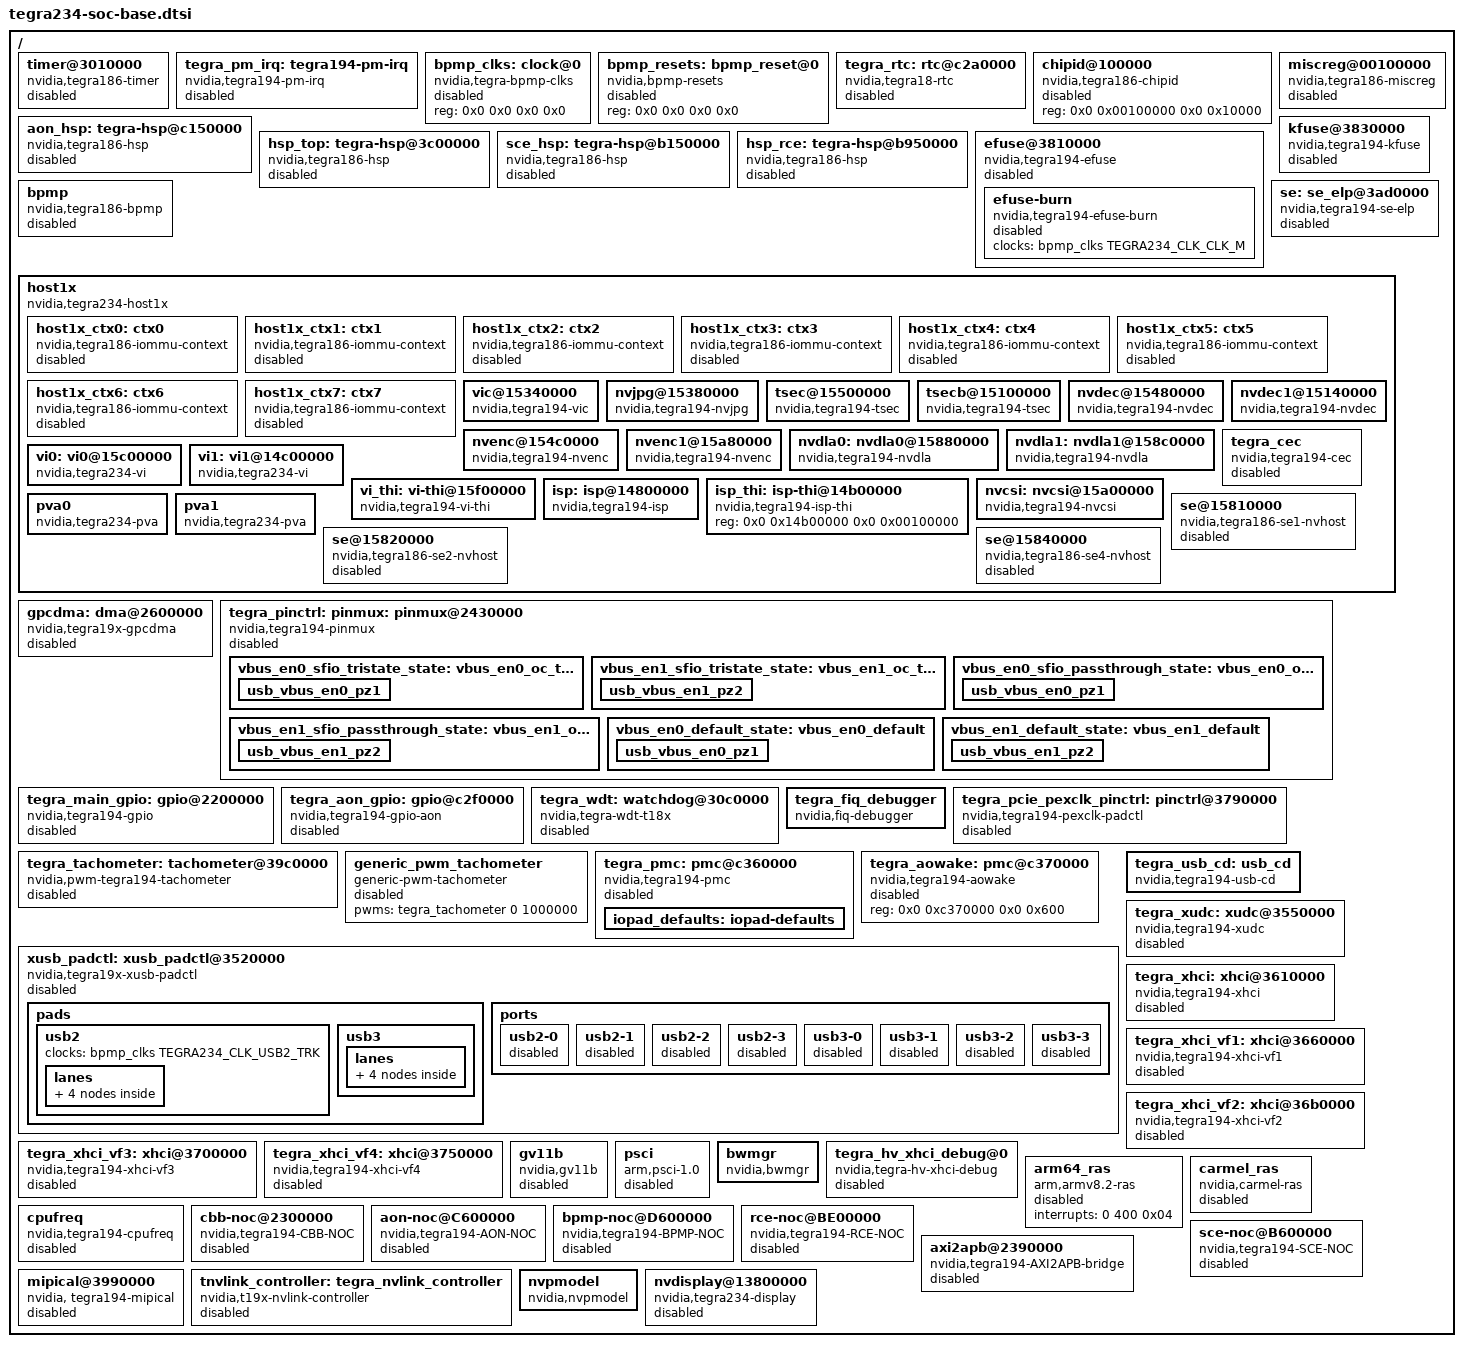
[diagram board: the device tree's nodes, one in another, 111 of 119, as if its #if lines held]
/*
 * Copyright (c) 2014-2019, NVIDIA CORPORATION.  All rights reserved.
 *
 * This program is free software; you can redistribute it and/or modify
 * it under the terms of the GNU General Public License as published by
 * the Free Software Foundation; version 2 of the License.
 *
 * This program is distributed in the hope that it will be useful, but WITHOUT
 * ANY WARRANTY; without even the implied warranty of MERCHANTABILITY or
 * FITNESS FOR A PARTICULAR PURPOSE.  See the GNU General Public License for
 * more details.
 *
 * You should have received a copy of the GNU General Public License along
 * with this program; if not, write to the Free Software Foundation, Inc.,
 * 51 Franklin Street, Fifth Floor, Boston, MA  02110-1301, USA.
 *
 */

/* FIXME: remove all the tegra194-*** headers */
#include <dt-bindings/version.h>
#include <dt-bindings/clock/tegra194-clock.h>
#include <dt-bindings/clock/tegra234-clock.h>
#include <dt-bindings/reset/tegra194-reset.h>
#include <dt-bindings/reset/tegra234-reset.h>
#include "dt-bindings/interrupt/tegra194-irq.h"
#include "dt-bindings/interrupt-controller/arm-gic.h"
#include "dt-bindings/soc/tegra194-powergate.h"
#include "dt-bindings/soc/tegra234-powergate.h"
#include <dt-bindings/interrupt-controller/irq.h>
#include <dt-bindings/gpio/tegra194-gpio.h>
#include "dt-bindings/soc/tegra194-powergate.h"
#include <dt-bindings/pinctrl/pinctrl-tegra.h>
/* Minimal.dtsi is to be included first as subsequent headers can
 *override the nodes.
 */
#include "tegra234-soc/tegra234-soc-minimal.dtsi"
#include "tegra234-soc/tegra234-soc-power-domain.dtsi"
#include "tegra234-soc-memory.dtsi"
#include "tegra234-trusty.dtsi"
#include "tegra234-soc-cbb.dtsi"
#include "tegra234-soc-pcie.dtsi"
#include "tegra234-soc-eqos.dtsi"
#include "tegra234-soc-uart.dtsi"
#include "tegra234-soc-sdhci.dtsi"
#include "tegra234-soc-ufshc.dtsi"
#include "tegra234-soc-spi.dtsi"
#include "tegra234-soc-pwm.dtsi"
#include "tegra234-soc-i2c.dtsi"
#include "tegra234-soc-can.dtsi"
#include "tegra234-soc-audio.dtsi"
#include "tegra234-safety-sce.dtsi"
#include "tegra234-camera.dtsi"
#include "tegra234-soc/tegra234-soc-actmon.dtsi"
#include "tegra234-soc/tegra234-aon.dtsi"
#include "tegra234-soc/tegra234-cpus.dtsi"
#include "tegra234-soc-thermal.dtsi"
#include "dt-bindings/soc/tegra-io-pads.h"

/ {

	timer@3010000 {
		/* Do not enable this node (SOC Timer) as ARM Generic Timer
		 * (DT node="timer") should be used instead
		 */
		compatible = "nvidia,tegra186-timer";
		interrupts = <0 0 4>,
			     <0 1 4>,
			     <0 2 4>,
			     <0 3 4>,
			     <0 4 4>,
			     <0 5 4>,
			     <0 6 4>,
			     <0 7 4>;
		clock-frequency = <19200000>;
		reg = <0x0 0x03010000 0x0 0x000e0000>;
		tmr-count = <10>;
		wdt-count = <3>;
		status = "disabled";
	};

	tegra_pm_irq: tegra194-pm-irq {
		compatible = "nvidia,tegra194-pm-irq";
		interrupt-controller;
		#interrupt-cells = <3>;
		interrupt-parent = <&intc>;
		status = "disabled";
	};

#if TEGRA_BPMP_FW_DT_VERSION <= DT_VERSION_1
	bpmp_clks: clock@0 {
		compatible = "nvidia,tegra-bpmp-clks";
		reg = <0x0 0x0 0x0 0x0>;
		#clock-cells = <1>;
		status = "disabled";
	};

	bpmp_resets: bpmp_reset@0 {
		compatible = "nvidia,bpmp-resets";
		reg = <0x0 0x0 0x0 0x0>;
		#reset-cells = <1>;
		status = "disabled";
	};
#endif

	tegra_rtc: rtc@c2a0000 {
		compatible = "nvidia,tegra18-rtc";
		reg = <0x0 0x0c2a0000 0x0 0x00010000>;
		interrupt-parent = <&tegra_pm_irq>;
		interrupts = <0 10 0x04>;
		status = "disabled";
	};

	chipid@100000 {
		compatible = "nvidia,tegra186-chipid";
		reg = <0x0 0x00100000 0x0 0x10000>;
		status = "disabled";
	};

	miscreg@00100000 {
		compatible = "nvidia,tegra186-miscreg";
		reg = <0x0 0x00100000 0x0 0xf000>, /* Chipid */
		    <0x0 0x0010f000 0x0 0x1000>; /* Straps */
		status = "disabled";
	};

	aon_hsp: tegra-hsp@c150000 {
		compatible = "nvidia,tegra186-hsp";
		reg = <0x0 0x0c150000 0x0 0x00090000>;
		interrupts =	<0 TEGRA194_IRQ_AON_HSP_SHARED_1 0x4>,
				<0 TEGRA194_IRQ_AON_HSP_SHARED_2 0x4>,
				<0 TEGRA194_IRQ_AON_HSP_SHARED_3 0x4>,
				<0 TEGRA194_IRQ_AON_HSP_SHARED_4 0x4>;
		interrupt-names = "shared1", "shared2", "shared3", "shared4";
		status = "disabled";
	};

	hsp_top: tegra-hsp@3c00000 {
		compatible = "nvidia,tegra186-hsp";
		reg = <0x0 0x03c00000 0x0 0x000a0000>;
		interrupts =	<0 176 0x4>,
				<0 TEGRA194_IRQ_TOP0_HSP_SHARED_0 0x4>,
				<0 TEGRA194_IRQ_TOP0_HSP_SHARED_1 0x4>,
				<0 TEGRA194_IRQ_TOP0_HSP_SHARED_2 0x4>,
				<0 TEGRA194_IRQ_TOP0_HSP_SHARED_3 0x4>,
				<0 TEGRA194_IRQ_TOP0_HSP_SHARED_4 0x4>,
				<0 TEGRA194_IRQ_TOP0_HSP_SHARED_5 0x4>,
				<0 TEGRA194_IRQ_TOP0_HSP_SHARED_6 0x4>,
				<0 TEGRA194_IRQ_TOP0_HSP_SHARED_7 0x4>;
		interrupt-names = "doorbell",
				"shared0", "shared1", "shared2", "shared3",
				"shared4", "shared5", "shared6", "shared7";
		nvidia,mbox-ie;
		status = "disabled";
	};

	sce_hsp: tegra-hsp@b150000 {
		compatible = "nvidia,tegra186-hsp";
		reg = <0x0 0x0b150000 0x0 0x00090000>;
		interrupts =	<0 TEGRA194_IRQ_SCE_HSP_SHARED_1 0x4>,
				<0 TEGRA194_IRQ_SCE_HSP_SHARED_2 0x4>,
				<0 TEGRA194_IRQ_SCE_HSP_SHARED_3 0x4>,
				<0 TEGRA194_IRQ_SCE_HSP_SHARED_4 0x4>;
		interrupt-names = "shared1", "shared2", "shared3", "shared4";
		nvidia,mbox-ie;
		status = "disabled";
	};

	hsp_rce: tegra-hsp@b950000 {
		compatible = "nvidia,tegra186-hsp";
		reg = <0x0 0x0b950000 0x0 0x00090000>;
		interrupts =	<0 TEGRA194_IRQ_RCE_HSP_SHARED_1 0x4>,
				<0 TEGRA194_IRQ_RCE_HSP_SHARED_2 0x4>,
				<0 TEGRA194_IRQ_RCE_HSP_SHARED_3 0x4>,
				<0 TEGRA194_IRQ_RCE_HSP_SHARED_4 0x4>;
		nvidia,mbox-ie;
		interrupt-names = "shared1", "shared2", "shared3", "shared4";
		status = "disabled";
	};

	efuse@3810000 {
		compatible = "nvidia,tegra194-efuse";
		reg = <0x0 0x03810000 0x0 0x600>;
		clocks = <&bpmp_clks TEGRA234_CLK_FUSE>,
		         <&bpmp_clks TEGRA234_CLK_CLK_M>;
		clock-names = "fuse", "clk_m";
		status = "disabled";
		efuse-burn {
			compatible = "nvidia,tegra194-efuse-burn";
			clocks = <&bpmp_clks TEGRA234_CLK_CLK_M>;
			clock-names = "clk_m";
			status = "disabled";
		};
	};

	kfuse@3830000 {
		compatible = "nvidia,tegra194-kfuse";
		reg = <0x0 0x3830000 0x0 0x10000>;
		clocks = <&bpmp_clks TEGRA234_CLK_KFUSE>;
		clock-names = "kfuse";
		status = "disabled";
	};

	bpmp: bpmp {
		compatible = "nvidia,tegra186-bpmp";
		iommus = <&smmu TEGRA_SID_BPMP>;
		dma-coherent;
		reg = <0x0 0x0d000000 0x0 0x00800000>,
		      <0x0 0x4004e000 0x0 0x00001000>,
		      <0x0 0x4004f000 0x0 0x00001000>;
		status = "disabled";
		#power-domain-cells = <1>;
		#strap-cells = <1>;
		#nvidia,controller-id-cells = <1>;
	};

	se: se_elp@3ad0000 {
		compatible = "nvidia,tegra194-se-elp";
		reg = <0x0 0x03ad0000 0x0 0x10000>,
		      <0x0 0x03ae0000 0x0 0x10000>;
		interrupts = <0 283 0x04>;
		clocks = <&bpmp_clks TEGRA234_CLK_SE>;
		clock-names = "se";
		pka1-rsa-priority = <300>;
		status = "disabled";
	};

	host1x: host1x {
		compatible = "nvidia,tegra234-host1x", "simple-bus";
		reg = <0x0 0x13e40000 0x0 0x00010000>,
		      <0x0 0x13e10000 0x0 0x00010000>,
		      <0x0 0x13ef0000 0x0 0x00040000>,
		      <0x0 0x60000000 0x0 0x00400000>,
		      <0x0 0x13e00000 0x0 0x00010000>;
		reg-names = "guest", "hypervisor", "actmon", "sem-syncpt-shim",
			"common";
		interrupts = <0 265 0x04>,
			     <0 263 0x04>;
		nvidia,ignore-dt-update;
		wakeup_capable;
		resets = <&bpmp_resets TEGRA194_RESET_HOST1X>;
		clocks = <&bpmp_clks TEGRA234_CLK_HOST1X>,
			 <&bpmp_clks TEGRA234_CLK_ACTMON>;
		clock-names = "host1x", "actmon";
		nvidia,vmid = <1>;

		iommus = <&smmu TEGRA_SID_HC>,
			 <&smmu TEGRA_SID_HC_VM0>,
			 <&smmu TEGRA_SID_HC_VM1>,
			 <&smmu TEGRA_SID_HC_VM2>,
			 <&smmu TEGRA_SID_HC_VM3>,
			 <&smmu TEGRA_SID_HC_VM4>,
			 <&smmu TEGRA_SID_HC_VM5>,
			 <&smmu TEGRA_SID_HC_VM6>,
			 <&smmu TEGRA_SID_HC_VM7>;
		dma-coherent;

		#address-cells = <2>;
		#size-cells = <2>;

		ranges;

		host1x_ctx0: ctx0 {
			compatible = "nvidia,tegra186-iommu-context";
			iommus = <&smmu TEGRA_SID_HOST1X_CTX0>;
			dma-coherent;
			status = "disabled";
		};

		host1x_ctx1: ctx1 {
			compatible = "nvidia,tegra186-iommu-context";
			iommus = <&smmu TEGRA_SID_HOST1X_CTX1>;
			dma-coherent;
			status = "disabled";
		};

		host1x_ctx2: ctx2 {
			compatible = "nvidia,tegra186-iommu-context";
			iommus = <&smmu TEGRA_SID_HOST1X_CTX2>;
			dma-coherent;
			status = "disabled";
		};

		host1x_ctx3: ctx3 {
			compatible = "nvidia,tegra186-iommu-context";
			iommus = <&smmu TEGRA_SID_HOST1X_CTX3>;
			dma-coherent;
			status = "disabled";
		};

		host1x_ctx4: ctx4 {
			compatible = "nvidia,tegra186-iommu-context";
			iommus = <&smmu TEGRA_SID_HOST1X_CTX4>;
			dma-coherent;
			status = "disabled";
		};

		host1x_ctx5: ctx5 {
			compatible = "nvidia,tegra186-iommu-context";
			iommus = <&smmu TEGRA_SID_HOST1X_CTX5>;
			dma-coherent;
			status = "disabled";
		};

		host1x_ctx6: ctx6 {
			compatible = "nvidia,tegra186-iommu-context";
			iommus = <&smmu TEGRA_SID_HOST1X_CTX6>;
			dma-coherent;
			status = "disabled";
		};

		host1x_ctx7: ctx7 {
			compatible = "nvidia,tegra186-iommu-context";
			iommus = <&smmu TEGRA_SID_HOST1X_CTX7>;
			dma-coherent;
			status = "disabled";
		};

		vic@15340000 {
			compatible = "nvidia,tegra194-vic";
			power-domains = <&bpmp TEGRA234_POWER_DOMAIN_VIC>;
			reg = <0x0 0x15340000 0x0 0x00040000>;
			interrupts = <0 206 0x04>;

			resets = <&bpmp_resets TEGRA234_RESET_VIC>;
			clocks = <&bpmp_clks TEGRA234_CLK_VIC>;
			clock-names = "vic";

			iommus = <&smmu TEGRA_SID_VIC>;
			dma-coherent;
		};

		nvjpg@15380000 {
			compatible = "nvidia,tegra194-nvjpg";
			power-domains = <&bpmp TEGRA234_POWER_DOMAIN_NVJPG>;
			reg = <0x0 0x15380000 0x0 0x00040000>;
			resets = <&bpmp_resets TEGRA234_RESET_NVJPG>;
			clocks = <&bpmp_clks TEGRA234_CLK_NVJPG>;
			clock-names = "nvjpg";

			iommus = <&smmu TEGRA_SID_NVJPG>;
			dma-coherent;
		};

		tsec@15500000 {
			compatible = "nvidia,tegra194-tsec";
			reg = <0x0 0x15500000 0x0 0x00040000>;
			resets = <&bpmp_resets TEGRA234_RESET_TSEC>;
			clocks = <&bpmp_clks TEGRA234_CLK_TSEC>;
			clock-names = "tsec";

			iommus = <&smmu TEGRA_SID_TSEC>;
			dma-coherent;
		};

		tsecb@15100000 {
			compatible = "nvidia,tegra194-tsec";
			reg = <0x0 0x15100000 0x0 0x00040000>;
			resets = <&bpmp_resets TEGRA234_RESET_TSECB>;
			clocks = <&bpmp_clks TEGRA234_CLK_TSECB>;
			clock-names = "tsecb";

			iommus = <&smmu TEGRA_SID_TSECB>;
			dma-coherent;
		};

		nvdec@15480000 {
			compatible = "nvidia,tegra194-nvdec";
			power-domains = <&bpmp TEGRA234_POWER_DOMAIN_NVDECA>;
			reg = <0x0 0x15480000 0x0 0x00040000>;
			resets = <&bpmp_resets TEGRA194_RESET_NVDEC>;
			clocks = <&bpmp_clks TEGRA234_CLK_NVDEC>,
				 <&bpmp_clks TEGRA234_CLK_KFUSE>,
				 <&bpmp_clks TEGRA234_CLK_FUSE>;
			clock-names = "nvdec", "kfuse", "efuse";

			iommus = <&smmu TEGRA_SID_NVDEC>;
			dma-coherent;
		};

		nvdec1@15140000 {
			compatible = "nvidia,tegra194-nvdec";
			power-domains = <&bpmp TEGRA234_POWER_DOMAIN_NVDECB>;
			reg = <0x0 0x15140000 0x0 0x00040000>;
			resets = <&bpmp_resets TEGRA234_RESET_NVDEC1>;
			clocks = <&bpmp_clks TEGRA234_CLK_NVDEC1>,
				 <&bpmp_clks TEGRA234_CLK_KFUSE>,
				 <&bpmp_clks TEGRA234_CLK_FUSE>;
			clock-names = "nvdec", "kfuse", "efuse";

			iommus = <&smmu TEGRA_SID_NVDEC1>;
			dma-coherent;
		};

		nvenc@154c0000 {
			compatible = "nvidia,tegra194-nvenc";
			power-domains = <&bpmp TEGRA234_POWER_DOMAIN_NVENCA>;
			reg = <0x0 0x154c0000 0x0 0x00040000>;
			resets = <&bpmp_resets TEGRA234_RESET_NVENC>;
			clocks = <&bpmp_clks TEGRA234_CLK_NVENC>;
			clock-names = "nvenc";

			iommus = <&smmu TEGRA_SID_NVENC>;
			dma-coherent;
		};

		nvenc1@15a80000 {
			compatible = "nvidia,tegra194-nvenc";
			power-domains = <&bpmp TEGRA234_POWER_DOMAIN_NVENCB>;
			reg = <0x0 0x15a80000 0x0 0x00040000>;
			resets = <&bpmp_resets TEGRA234_RESET_NVENC1>;
			clocks = <&bpmp_clks TEGRA234_CLK_NVENC1>;
			clock-names = "nvenc";

			iommus = <&smmu TEGRA_SID_NVENC1>;
			dma-coherent;
		};

		nvdla0: nvdla0@15880000 {
			compatible = "nvidia,tegra194-nvdla";
			power-domains = <&bpmp TEGRA234_POWER_DOMAIN_DLAA>;
			reg = <0x0 0x15880000 0x0 0x00040000>;
			interrupts = <0 236 0x04>;

			resets = <&bpmp_resets TEGRA234_RESET_DLA0>;
			clocks = <&bpmp_clks TEGRA234_CLK_DLA0_CORE>,
				 <&bpmp_clks TEGRA234_CLK_DLA0_FALCON>;
			clock-names = "nvdla0", "nvdla0_flcn";

			iommus = <&smmu TEGRA_SID_NVDLA0>;
			dma-coherent;
		};

		nvdla1: nvdla1@158c0000 {
			compatible = "nvidia,tegra194-nvdla";
			power-domains = <&bpmp TEGRA234_POWER_DOMAIN_DLAB>;
			reg = <0x0 0x158c0000 0x0 0x00040000>;
			interrupts = <0 237 0x04>;

			resets = <&bpmp_resets TEGRA234_RESET_DLA1>;
			clocks = <&bpmp_clks TEGRA234_CLK_DLA1_CORE>,
				 <&bpmp_clks TEGRA234_CLK_DLA1_FALCON>;
			clock-names = "nvdla1", "nvdla1_flcn";

			iommus = <&smmu TEGRA_SID_NVDLA1>;
			dma-coherent;
		};

		tegra_cec: tegra_cec {
			status = "disabled";
			compatible = "nvidia,tegra194-cec";
			reg = <0x0 0x03960000 0x0 0x00001000>;
			interrupts = <0 162 0x04>;
			clocks = <&bpmp_clks TEGRA234_CLK_CEC>;
			clock-names = "cec";
		};

		vi0: vi0@15c00000 {
			compatible = "nvidia,tegra234-vi";
			reg = <0x0 0x15c00000 0x0 0x00300000>,
				<0x0 0x15f00000 0x0 0x00100000>;
			resets = <&bpmp_resets TEGRA234_RESET_VI>,
				 <&bpmp_resets TEGRA234_RESET_TSCTNVI>;
			reset-names = "vi", "tsctnvi";
			clocks = <&bpmp_clks TEGRA234_CLK_VI>,
				 <&bpmp_clks TEGRA234_CLK_VI_CONST>,
				 <&bpmp_clks TEGRA234_CLK_NVCSI>,
				 <&bpmp_clks TEGRA234_CLK_NVCSILP>;
			clock-names = "vi", "vi-const", "nvcsi", "nvcsilp";

			nvidia,vi-falcon-device = <&vi_thi>;

			iommus = <&smmu TEGRA_SID_VI>;
			iso-smmu;
			non-coherent;
		};

		vi1: vi1@14c00000 {
			compatible = "nvidia,tegra234-vi";
			reg = <0x0 0x14c00000 0x0 0x00300000>;
			resets = <&bpmp_resets TEGRA234_RESET_VI>,
				 <&bpmp_resets TEGRA234_RESET_TSCTNVI>;
			reset-names = "vi", "tsctnvi";
			clocks = <&bpmp_clks TEGRA234_CLK_VI>,
				 <&bpmp_clks TEGRA234_CLK_VI_CONST>,
				 <&bpmp_clks TEGRA234_CLK_NVCSI>,
				 <&bpmp_clks TEGRA234_CLK_NVCSILP>;
			clock-names = "vi", "vi-const", "nvcsi", "nvcsilp";

			nvidia,vi-falcon-device = <&vi_thi>;

			iommus = <&smmu TEGRA_SID_VI2>;
			iso-smmu;
			non-coherent;
		};

		vi_thi: vi-thi@15f00000 {
			compatible = "nvidia,tegra194-vi-thi";

			/* vi-thi host1x is used for pixel injection tests */
			clocks = <&bpmp_clks TEGRA234_CLK_VI>,
			         <&bpmp_clks TEGRA234_CLK_VI_CONST>;
			clock-names = "vi", "vi-const";
		};

		isp: isp@14800000 {
			compatible = "nvidia,tegra194-isp";
			reg = <0x0 0x14800000 0x0 0x00010000>;

			resets = <&bpmp_resets TEGRA234_RESET_ISP>;
			reset-names = "isp";
			clocks = <&bpmp_clks TEGRA234_CLK_ISP>;
			clock-names = "isp";

			nvidia,isp-falcon-device = <&isp_thi>;

			iommus = <&smmu TEGRA_SID_ISP>;
			dma-coherent;
		};

		isp_thi: isp-thi@14b00000 {
			compatible = "nvidia,tegra194-isp-thi";
                        reg = <0x0 0x14b00000 0x0 0x00100000>;
		};

		nvcsi: nvcsi@15a00000 {
			compatible = "nvidia,tegra194-nvcsi";
			reg = <0x0 0x15a00000 0x0 0x00050000>;
			power-domains = <&bpmp TEGRA234_POWER_DOMAIN_VE>;
			resets = <&bpmp_resets TEGRA234_RESET_NVCSI>;
			clocks = <&bpmp_clks TEGRA234_CLK_NVCSI>,
				 <&bpmp_clks TEGRA234_CLK_NVCSILP>;
			clock-names = "nvcsi", "nvcsilp";
			interrupts = <0 119 0x04>;
			num-ports = <6>;
		};

		pva0: pva0 {
			compatible = "nvidia,tegra234-pva";
			power-domains = <&bpmp TEGRA234_POWER_DOMAIN_PVAA>;
			reg = <0x0 0x16000000 0x0 0x800000>;
			interrupts = <0 234 0x04>;

			resets = <&bpmp_resets TEGRA234_RESET_PVA0_ALL>;
			clocks = <&bpmp_clks TEGRA234_CLK_PVA0_AXI>,
				 <&bpmp_clks TEGRA234_CLK_PVA0_VPS0>,
				 <&bpmp_clks TEGRA234_CLK_PVA0_VPS1>;
			clock-names = "axi", "vps0", "vps1";

			iommus = <&smmu TEGRA_SID_PVA0>;
			dma-coherent;
		};

		pva1: pva1 {
			compatible = "nvidia,tegra234-pva";
			power-domains = <&bpmp TEGRA234_POWER_DOMAIN_PVAB>;
			reg = <0x0 0x16800000 0x0 0x800000>;
			interrupts = <0 235 0x04>;

			resets = <&bpmp_resets TEGRA234_RESET_PVA1_ALL>;
			clocks = <&bpmp_clks TEGRA234_CLK_PVA1_AXI>,
				 <&bpmp_clks TEGRA234_CLK_PVA1_VPS0>,
				 <&bpmp_clks TEGRA234_CLK_PVA1_VPS1>;
			clock-names = "axi", "vps0", "vps1";

			iommus = <&smmu TEGRA_SID_PVA1>;
			dma-coherent;
		};

		se@15810000 {
			compatible = "nvidia,tegra186-se1-nvhost";
			reg = <0x0 0x15810000 0x0 0x10000>;
			supported-algos = "drbg";
			nvidia,io-coherent;
			opcode_addr = <0x204>;
			resets = <&bpmp_resets TEGRA234_RESET_SE>;
			clocks = <&bpmp_clks TEGRA234_CLK_SE>;
			clock-names = "se";

			iommus = <&smmu TEGRA_SID_SE>;
			dma-coherent;

			status = "disabled";
		};

		se@15820000 {
			compatible = "nvidia,tegra186-se2-nvhost";
			reg = <0x0 0x15820000 0x0 0x10000>;
			supported-algos = "xts", "aes", "cmac";
			nvidia,io-coherent;
			opcode_addr = <0x404>;
			resets = <&bpmp_resets TEGRA234_RESET_SE>;
			clocks = <&bpmp_clks TEGRA234_CLK_SE>;
			clock-names = "se";

			iommus = <&smmu TEGRA_SID_SE1>;
			dma-coherent;

			status = "disabled";
		};

		se@15840000 {
			compatible = "nvidia,tegra186-se4-nvhost";
			reg = <0x0 0x15840000 0x0 0x10000>;
			supported-algos = "sha";
			nvidia,io-coherent;
			opcode_addr = <0x104>;
			resets = <&bpmp_resets TEGRA234_RESET_SE>;
			clocks = <&bpmp_clks TEGRA234_CLK_SE>;
			clock-names = "se";

			iommus = <&smmu TEGRA_SID_SE2>;
			dma-coherent;

			status = "disabled";
		};
	}; // host1x

	gpcdma: dma@2600000 {
		compatible = "nvidia,tegra19x-gpcdma", "nvidia,tegra186-gpcdma";
		reg = <0x0 0x2600000 0x0 0x210000>;
		resets = <&bpmp_resets TEGRA194_RESET_GPCDMA>;
		reset-names = "gpcdma";
		interrupts = <0 75 0x04
			0 76 0x04
			0 77 0x04
			0 78 0x04
			0 79 0x04
			0 80 0x04
			0 81 0x04
			0 82 0x04
			0 83 0x04
			0 84 0x04
			0 85 0x04
			0 86 0x04
			0 87 0x04
			0 88 0x04
			0 89 0x04
			0 90 0x04
			0 91 0x04
			0 92 0x04
			0 93 0x04
			0 94 0x04
			0 95 0x04
			0 96 0x04
			0 97 0x04
			0 98 0x04
			0 99 0x04
			0 100 0x04
			0 101 0x04
			0 102 0x04
			0 103 0x04
			0 104 0x04
			0 105 0x04
			0 106 0x04
			0 107 0x04>;
		#dma-cells = <1>;

		iommus = <&smmu TEGRA_SID_GPCDMA_0>;
		dma-coherent;

		status = "disabled";
	};

	tegra_pinctrl: pinmux: pinmux@2430000 {
		compatible = "nvidia,tegra194-pinmux";
		reg = <0x0 0x2430000 0x0 0x17000
			0x0 0xc300000 0x0 0x4000>;
		#gpio-range-cells = <3>;
		status = "disabled";

		vbus_en0_sfio_tristate_state: vbus_en0_oc_tristate {
			usb_vbus_en0_pz1 {
				nvidia,pins = "usb_vbus_en0_pz1";
				nvidia,function = "usb";
				nvidia,tristate = <TEGRA_PIN_ENABLE>;
				nvidia,io-high-voltage = <TEGRA_PIN_ENABLE>;
				nvidia,enable-input = <TEGRA_PIN_ENABLE>;
			};
		};
		vbus_en1_sfio_tristate_state: vbus_en1_oc_tristate {
			usb_vbus_en1_pz2 {
				nvidia,pins = "usb_vbus_en1_pz2";
				nvidia,function = "usb";
				nvidia,tristate = <TEGRA_PIN_ENABLE>;
				nvidia,io-high-voltage = <TEGRA_PIN_ENABLE>;
				nvidia,enable-input = <TEGRA_PIN_ENABLE>;
			};
		};
		vbus_en0_sfio_passthrough_state: vbus_en0_oc_passthrough {
			usb_vbus_en0_pz1 {
				nvidia,pins = "usb_vbus_en0_pz1";
				nvidia,function = "usb";
				nvidia,tristate = <TEGRA_PIN_DISABLE>;
				nvidia,io-high-voltage = <TEGRA_PIN_ENABLE>;
				nvidia,enable-input = <TEGRA_PIN_ENABLE>;
			};
		};
		vbus_en1_sfio_passthrough_state: vbus_en1_oc_passthrough {
			usb_vbus_en1_pz2 {
				nvidia,pins = "usb_vbus_en1_pz2";
				nvidia,function = "usb";
				nvidia,tristate = <TEGRA_PIN_DISABLE>;
				nvidia,io-high-voltage = <TEGRA_PIN_ENABLE>;
				nvidia,enable-input = <TEGRA_PIN_ENABLE>;
			};
		};
		vbus_en0_default_state: vbus_en0_default {
			usb_vbus_en0_pz1 {
				nvidia,pins = "usb_vbus_en0_pz1";
				nvidia,function = "rsvd1";
				nvidia,io-high-voltage = <TEGRA_PIN_ENABLE>;
				nvidia,enable-input = <TEGRA_PIN_ENABLE>;
			};
		};
		vbus_en1_default_state: vbus_en1_default {
			usb_vbus_en1_pz2 {
				nvidia,pins = "usb_vbus_en1_pz2";
				nvidia,function = "rsvd1";
				nvidia,io-high-voltage = <TEGRA_PIN_ENABLE>;
				nvidia,enable-input = <TEGRA_PIN_ENABLE>;
			};
		};
	};

	tegra_main_gpio: gpio@2200000 {
		compatible = "nvidia,tegra194-gpio";
		reg-names = "security", "gpio";
		reg =
			<0x0 0x2200000 0x0 0x10000>,
			<0x0 0x2210000 0x0 0x10000>;
		interrupts =
			<0 TEGRA194_IRQ_GPIO0_0 IRQ_TYPE_LEVEL_HIGH>,
			<0 TEGRA194_IRQ_GPIO0_1 IRQ_TYPE_LEVEL_HIGH>,
			<0 TEGRA194_IRQ_GPIO0_2 IRQ_TYPE_LEVEL_HIGH>,
			<0 TEGRA194_IRQ_GPIO0_3 IRQ_TYPE_LEVEL_HIGH>,
			<0 TEGRA194_IRQ_GPIO0_4 IRQ_TYPE_LEVEL_HIGH>,
			<0 TEGRA194_IRQ_GPIO0_5 IRQ_TYPE_LEVEL_HIGH>,
			<0 TEGRA194_IRQ_GPIO0_6 IRQ_TYPE_LEVEL_HIGH>,
			<0 TEGRA194_IRQ_GPIO0_7 IRQ_TYPE_LEVEL_HIGH>,
			<0 TEGRA194_IRQ_GPIO1_0 IRQ_TYPE_LEVEL_HIGH>,
			<0 TEGRA194_IRQ_GPIO1_1 IRQ_TYPE_LEVEL_HIGH>,
			<0 TEGRA194_IRQ_GPIO1_2 IRQ_TYPE_LEVEL_HIGH>,
			<0 TEGRA194_IRQ_GPIO1_3 IRQ_TYPE_LEVEL_HIGH>,
			<0 TEGRA194_IRQ_GPIO1_4 IRQ_TYPE_LEVEL_HIGH>,
			<0 TEGRA194_IRQ_GPIO1_5 IRQ_TYPE_LEVEL_HIGH>,
			<0 TEGRA194_IRQ_GPIO1_6 IRQ_TYPE_LEVEL_HIGH>,
			<0 TEGRA194_IRQ_GPIO1_7 IRQ_TYPE_LEVEL_HIGH>,
			<0 TEGRA194_IRQ_GPIO2_0 IRQ_TYPE_LEVEL_HIGH>,
			<0 TEGRA194_IRQ_GPIO2_1 IRQ_TYPE_LEVEL_HIGH>,
			<0 TEGRA194_IRQ_GPIO2_2 IRQ_TYPE_LEVEL_HIGH>,
			<0 TEGRA194_IRQ_GPIO2_3 IRQ_TYPE_LEVEL_HIGH>,
			<0 TEGRA194_IRQ_GPIO2_4 IRQ_TYPE_LEVEL_HIGH>,
			<0 TEGRA194_IRQ_GPIO2_5 IRQ_TYPE_LEVEL_HIGH>,
			<0 TEGRA194_IRQ_GPIO2_6 IRQ_TYPE_LEVEL_HIGH>,
			<0 TEGRA194_IRQ_GPIO2_7 IRQ_TYPE_LEVEL_HIGH>,
			<0 TEGRA194_IRQ_GPIO3_0 IRQ_TYPE_LEVEL_HIGH>,
			<0 TEGRA194_IRQ_GPIO3_1 IRQ_TYPE_LEVEL_HIGH>,
			<0 TEGRA194_IRQ_GPIO3_2 IRQ_TYPE_LEVEL_HIGH>,
			<0 TEGRA194_IRQ_GPIO3_3 IRQ_TYPE_LEVEL_HIGH>,
			<0 TEGRA194_IRQ_GPIO3_4 IRQ_TYPE_LEVEL_HIGH>,
			<0 TEGRA194_IRQ_GPIO3_5 IRQ_TYPE_LEVEL_HIGH>,
			<0 TEGRA194_IRQ_GPIO3_6 IRQ_TYPE_LEVEL_HIGH>,
			<0 TEGRA194_IRQ_GPIO3_7 IRQ_TYPE_LEVEL_HIGH>,
			<0 TEGRA194_IRQ_GPIO4_0 IRQ_TYPE_LEVEL_HIGH>,
			<0 TEGRA194_IRQ_GPIO4_1 IRQ_TYPE_LEVEL_HIGH>,
			<0 TEGRA194_IRQ_GPIO4_2 IRQ_TYPE_LEVEL_HIGH>,
			<0 TEGRA194_IRQ_GPIO4_3 IRQ_TYPE_LEVEL_HIGH>,
			<0 TEGRA194_IRQ_GPIO4_4 IRQ_TYPE_LEVEL_HIGH>,
			<0 TEGRA194_IRQ_GPIO4_5 IRQ_TYPE_LEVEL_HIGH>,
			<0 TEGRA194_IRQ_GPIO4_6 IRQ_TYPE_LEVEL_HIGH>,
			<0 TEGRA194_IRQ_GPIO4_7 IRQ_TYPE_LEVEL_HIGH>,
			<0 TEGRA194_IRQ_GPIO5_0 IRQ_TYPE_LEVEL_HIGH>,
			<0 TEGRA194_IRQ_GPIO5_1 IRQ_TYPE_LEVEL_HIGH>,
			<0 TEGRA194_IRQ_GPIO5_2 IRQ_TYPE_LEVEL_HIGH>,
			<0 TEGRA194_IRQ_GPIO5_3 IRQ_TYPE_LEVEL_HIGH>,
			<0 TEGRA194_IRQ_GPIO5_4 IRQ_TYPE_LEVEL_HIGH>,
			<0 TEGRA194_IRQ_GPIO5_5 IRQ_TYPE_LEVEL_HIGH>,
			<0 TEGRA194_IRQ_GPIO5_6 IRQ_TYPE_LEVEL_HIGH>,
			<0 TEGRA194_IRQ_GPIO5_7 IRQ_TYPE_LEVEL_HIGH>;
		gpio-controller;
		#gpio-cells = <2>;
		interrupt-controller;
		#interrupt-cells = <2>;
		gpio-ranges =
			<&tegra_pinctrl TEGRA194_MAIN_GPIO_BASE(A) TEGRA_PIN_BASE(A) TEGRA194_MAIN_GPIO_RANGE(A, Z) >,
			<&tegra_pinctrl TEGRA194_MAIN_GPIO_BASE(FF) TEGRA_PIN_BASE(FF) TEGRA194_MAIN_GPIO_RANGE(FF, GG) >;
		status = "disabled";
	};

	tegra_aon_gpio: gpio@c2f0000 {
		compatible = "nvidia,tegra194-gpio-aon";
		reg-names = "security", "gpio";
		reg = 	<0x0 0xc2f0000 0x0 0x1000>,
			<0x0 0xc2f1000 0x0 0x1000>;
		interrupts =
			<0 TEGRA194_IRQ_AON_GPIO_0 IRQ_TYPE_LEVEL_HIGH>,
			<0 TEGRA194_IRQ_AON_GPIO_1 IRQ_TYPE_LEVEL_HIGH>,
			<0 TEGRA194_IRQ_AON_GPIO_2 IRQ_TYPE_LEVEL_HIGH>,
			<0 TEGRA194_IRQ_AON_GPIO_3 IRQ_TYPE_LEVEL_HIGH>;
		status = "disabled";
		gpio-controller;
		#gpio-cells = <2>;
		interrupt-controller;
		#interrupt-cells = <2>;
		gpio-ranges =
			<&tegra_pinctrl TEGRA194_AON_GPIO_BASE(AA) TEGRA_PIN_BASE(AA) TEGRA194_AON_GPIO_RANGE(AA, EE) >;
	};

	tegra_wdt:watchdog@30c0000 {
		compatible = "nvidia,tegra-wdt-t18x";
		reg = <0x0 0x030c0000 0x0 0x10000>, /* WDT0 */
		      <0x0 0x03020000 0x0 0x10000>, /* TMR0 */
		      <0x0 0x03010000 0x0 0x10000>; /* TKE */
		interrupts = <0 7 0x4 0 8 0x4>; /* TKE shared int */
		nvidia,watchdog-index = <0>;
		nvidia,timer-index = <7>;
		nvidia,expiry-count = <5>;
		nvidia,enable-on-init;
		nvidia,extend-watchdog-suspend;
		timeout-sec = <120>;
		nvidia,disable-debug-reset;
		status = "disabled";
	};

	tegra_fiq_debugger {
		compatible = "nvidia,fiq-debugger";
		use-console-port;
		interrupts = <0 17 0x4>;
	};

	tegra_pcie_pexclk_pinctrl: pinctrl@3790000 {
		compatible = "nvidia,tegra194-pexclk-padctl";
		reg = <0x0 0x03790000 0x0 0x1000>,
		      <0x0 0x037a0000 0x0 0x1000>;
		status = "disabled";
	};

	tegra_tachometer: tachometer@39c0000 {
		compatible = "nvidia,pwm-tegra194-tachometer";
		reg = <0x0 0x039c0000 0x0 0x10>;
		#pwm-cells = <2>;
		clocks = <&bpmp_clks TEGRA234_CLK_TACH>;
		clock-names = "tach";
		resets = <&bpmp_resets TEGRA194_RESET_TACH>;
		reset-names = "tach";
		pulse-per-rev = <2>;
		capture-window-length = <2>;
		disable-clk-gate;
		status = "disabled";
	};

	generic_pwm_tachometer {
		compatible = "generic-pwm-tachometer";
		pwms = <&tegra_tachometer 0 1000000>;
		status = "disabled";
	};

	tegra_pmc: pmc@c360000 {
		compatible = "nvidia,tegra194-pmc";
		reg = <0x0 0xC360000 0x0 0x400
			0x0 0xC390000 0x0 0x2fff
			0x0 0xC3a0000 0x0 0xfff>;
		#padcontroller-cells = <1>;
		nvidia,restrict-voltage-switch;
		pinctrl-names = "default";
		pinctrl-0 = <&iopad_defaults>;
		status = "disabled";
		iopad_defaults: iopad-defaults {
		};
	};

	tegra_aowake: pmc@c370000 {
		compatible = "nvidia,tegra194-aowake";
		reg = <0x0 0xc370000 0x0 0x600>;
		status = "disabled";
	};


	xusb_padctl: xusb_padctl@3520000 {
		compatible = "nvidia,tegra19x-xusb-padctl";
		reg = <0x0 0x03520000 0x0 0x1000>,
			<0x0 0x03540000 0x0 0x1000>;
		reg-names = "padctl", "ao";
		interrupts = <0 167 0x4>;
		resets = <&bpmp_resets TEGRA194_RESET_XUSB_PADCTL>;
		reset-names = "padctl";
		status = "disabled";

		pads {
			usb2 {
				clocks = <&bpmp_clks TEGRA234_CLK_USB2_TRK>;
				clock-names = "trk";

				lanes {
					usb2-0 {
						status = "disabled";
						#phy-cells = <0>;
					};
					usb2-1 {
						status = "disabled";
						#phy-cells = <0>;
					};
					usb2-2 {
						status = "disabled";
						#phy-cells = <0>;
					};
					usb2-3 {
						status = "disabled";
						#phy-cells = <0>;
					};
				};
			};
			usb3 {
				lanes {
					usb3-0 {
						status = "disabled";
						#phy-cells = <0>;
					};
					usb3-1 {
						status = "disabled";
						#phy-cells = <0>;
					};
					usb3-2 {
						status = "disabled";
						#phy-cells = <0>;
					};
					usb3-3 {
						status = "disabled";
						#phy-cells = <0>;
					};
				};
			};
		};

		ports {
			usb2-0 {
				status = "disabled";
			};
			usb2-1 {
				status = "disabled";
			};
			usb2-2 {
				status = "disabled";
			};
			usb2-3 {
				status = "disabled";
			};
			usb3-0 {
				status = "disabled";
			};
			usb3-1 {
				status = "disabled";
			};
			usb3-2 {
				status = "disabled";
			};
			usb3-3 {
				status = "disabled";
			};
		};
	};

	tegra_usb_cd: usb_cd {
		compatible = "nvidia,tegra194-usb-cd";
		nvidia,xusb-padctl = <&xusb_padctl>;
		phys = <&{/xusb_padctl@3520000/pads/usb2/lanes/usb2-0}>;
		phy-names = "otg-phy";
		status = "okay";
	};

	tegra_xudc: xudc@3550000 {
		compatible = "nvidia,tegra194-xudc";
		reg = <0x0 0x03550000 0x0 0x8000>,
			<0x0 0x03558000 0x0 0x1000>;
		interrupts = <0 166 0x4>;
		clocks = <&bpmp_clks TEGRA234_CLK_XUSB_CORE_DEV>,
			<&bpmp_clks TEGRA234_CLK_XUSB_SS_SUPERSPEED>,
			<&bpmp_clks TEGRA234_CLK_XUSB_SS>,
			<&bpmp_clks TEGRA234_CLK_XUSB_FS>;

		nvidia,xusb-padctl = <&xusb_padctl>;

		iommus = <&smmu TEGRA_SID_XUSB_DEV>;
		dma-coherent;

		status = "disabled";
		charger-detector = <&tegra_usb_cd>;
	};

	tegra_xhci: xhci@3610000 {
		compatible = "nvidia,tegra194-xhci";
		reg = <0x0 0x03610000 0x0 0x40000>,
			<0x0 0x03600000 0x0 0x10000>;
		interrupts = <0 163 0x4>, <0 164 0x4>, <0 167 0x4>;
		interrupt-parent = <&tegra_pm_irq>;

		clocks = <&bpmp_clks TEGRA234_CLK_XUSB_CORE_MUX>,
			<&bpmp_clks TEGRA234_CLK_XUSB_CORE_HOST>,
			<&bpmp_clks TEGRA234_CLK_XUSB_CORE_SS>,
			<&bpmp_clks TEGRA234_CLK_XUSB_FALCON>,
			<&bpmp_clks TEGRA234_CLK_XUSB_FALCON_HOST>,
			<&bpmp_clks TEGRA234_CLK_XUSB_FALCON_SS>,
			<&bpmp_clks TEGRA234_CLK_XUSB_FS>,
			<&bpmp_clks TEGRA234_CLK_XUSB_FS_HOST>,
			<&bpmp_clks TEGRA234_CLK_XUSB_SS>,
			<&bpmp_clks TEGRA234_CLK_XUSB_SS_SUPERSPEED>,
			<&bpmp_clks TEGRA234_CLK_UTMIPLL>,
			<&bpmp_clks TEGRA234_CLK_CLK_M>,
			<&bpmp_clks TEGRA234_CLK_PLLE>;
		clock-names = "xusb_hs_src", "xusb_host",
			"xusb_core_superspeed_clk", "xusb_falcon_src",
			"xusb_falcon_host_clk", "xusb_falcon_superspeed_clk",
			"xusb_fs_src", "xusb_fs_host_clk", "xusb_ss_src",
			"xusb_ss", "pll_u_480m", "clk_m", "pll_e";

		nvidia,xusb-padctl = <&xusb_padctl>;

		iommus = <&smmu TEGRA_SID_XUSB_HOST>;
		dma-coherent;

		status = "disabled";
	};

	tegra_xhci_vf1: xhci@3660000 {
		compatible = "nvidia,tegra194-xhci-vf1";
		reg = <0x0 0x03660000 0x0 0x40000>;
		interrupts = <0 21 0x4>;

		nvidia,xusb-padctl = <&xusb_padctl>;

		iommus = <&smmu TEGRA_SID_XUSB_VF0>;
		dma-coherent;

		status = "disabled";
	};

	tegra_xhci_vf2: xhci@36b0000 {
		compatible = "nvidia,tegra194-xhci-vf2";
		reg = <0x0 0x036b0000 0x0 0x40000>;
		interrupts = <0 22 0x4>;

		nvidia,xusb-padctl = <&xusb_padctl>;

		iommus = <&smmu TEGRA_SID_XUSB_VF1>;
		dma-coherent;

		status = "disabled";
	};

	tegra_xhci_vf3: xhci@3700000 {
		compatible = "nvidia,tegra194-xhci-vf3";
		reg = <0x0 0x03700000 0x0 0x40000>;
		interrupts = <0 23 0x4>;

		nvidia,xusb-padctl = <&xusb_padctl>;

		iommus = <&smmu TEGRA_SID_XUSB_VF2>;
		dma-coherent;

		status = "disabled";
	};

	tegra_xhci_vf4: xhci@3750000 {
		compatible = "nvidia,tegra194-xhci-vf4";
		reg = <0x0 0x03750000 0x0 0x40000>;
		interrupts = <0 24 0x4>;

		nvidia,xusb-padctl = <&xusb_padctl>;

		iommus = <&smmu TEGRA_SID_XUSB_VF3>;
		dma-coherent;

		status = "disabled";
	};

	gv11b {
		compatible = "nvidia,gv11b";
		reg = <0x0 0x17000000 0x0 0x1000000
		       0x0 0x18000000 0x0 0x1000000
		       0x0 0x03b41000 0x0 0x00001000>;
		interrupts = <0 70 0x04
		              0 71 0x04>;
		dma-noncontig;
		interrupt-names = "stall", "nonstall";
		nvidia,host1x = <&host1x>;
		access-vpr-phys;
		clocks = <&bpmp_clks TEGRA234_CLK_GPCCLK>,
			<&bpmp_clks TEGRA234_CLK_GPU_PWR>;
		clock-names = "gpu", "gpu_sys";
		resets = <&bpmp_resets TEGRA194_RESET_GPU>;
		dma-coherent;
		status = "disabled";
	};

	psci {
		compatible = "arm,psci-1.0";
		method = "smc";
		cpu_off = <0x84000002>;
		cpu_on = <0xC4000003>;
		cpu_suspend = <0xC4000001>;
		status = "disabled";
	};

	bwmgr: bwmgr {
		compatible = "nvidia,bwmgr";
		clocks = <&bpmp_clks TEGRA234_CLK_EMC>;
		clock-names = "emc";
		cdev-type = "bwmgr-therm-handler";
		cooling-min-state = <0>;
		cooling-max-state = <1>;
		#cooling-cells = <2>;
		status = "okay";
	};

	tegra_hv_xhci_debug@0 {
		compatible = "nvidia,tegra-hv-xhci-debug";
		status = "disabled";
	};

	arm64_ras: arm64_ras {
		compatible = "arm,armv8.2-ras";
		interrupts = <0 400 0x04>;
		status = "disabled";
	};

	carmel_ras {
		compatible = "nvidia,carmel-ras";
		status = "disabled";
	};

	cpufreq {
		compatible = "nvidia,tegra194-cpufreq";
		status = "disabled";
		cpu_emc_map = <1500000 800000>,
				<900000  665000>,
				<550000  408000>,
				<340000  204000>,
				<000000  102000>;
	};

	cbb-noc@2300000 {
		compatible = "nvidia,tegra194-CBB-NOC";
		reg = <0x0 0x02300000 0x0 0x1000>;
		interrupts = <0 230 4>, <0 231 4>;
		status = "disabled";
	};

	aon-noc@C600000 {
		compatible = "nvidia,tegra194-AON-NOC";
		reg = <0x0 0xC600000 0x0 0x1000>;
		interrupts = <0 260 4>, <0 172 4>;
		status = "disabled";
	};

	bpmp-noc@D600000 {
		compatible = "nvidia,tegra194-BPMP-NOC";
		reg = <0x0 0xD600000 0x0 0x1000>;
		interrupts = <0 262 4>, <0 174 4>;
		status = "disabled";
	};

	rce-noc@BE00000 {
		compatible = "nvidia,tegra194-RCE-NOC";
		reg = <0x0 0xBE00000 0x0 0x1000>;
		interrupts = <0 259 4>, <0 175 4>;
		status = "disabled";
	};

	sce-noc@B600000 {
		compatible = "nvidia,tegra194-SCE-NOC";
		reg = <0x0 0xB600000 0x0 0x1000>;
		interrupts = <0 261 4>, <0 173 4>;
		status = "disabled";
	};

	axi2apb@2390000 {
		compatible = "nvidia,tegra194-AXI2APB-bridge";
		reg = <0x0 0x02390000 0x0 0x1000>,
		    <0x0 0x023A0000 0x0 0x1000>,
		    <0x0 0x023B0000 0x0 0x1000>,
		    <0x0 0x023C0000 0x0 0x1000>,
		    <0x0 0x023D0000 0x0 0x1000>,
		    <0x0 0x023E0000 0x0 0x1000>;
		status = "disabled";
	};

	mipical@3990000{
		compatible = "nvidia, tegra194-mipical";
		reg = <0x0 0x03990000 0x0 0x10000>;
		clocks = <&bpmp_clks TEGRA234_CLK_MIPI_CAL>,
			<&bpmp_clks TEGRA234_CLK_UART_FST_MIPI_CAL>;
		clock-names = "mipi_cal", "uart_fs_mipi_cal";
		resets = <&bpmp_resets TEGRA194_RESET_MIPI_CAL>;
		reset-names = "mipi_cal";
		status = "disabled";
	};

	tnvlink_controller: tegra_nvlink_controller {
		compatible = "nvidia,t19x-nvlink-controller";
		reg = <0x0 0x3b80000 0x0 0x1000 /* NVLW_TIOCTRL */
		       0x0 0x3b84000 0x0 0x1000 /* NVLW_NVLIPT */
		       0x0 0x3b86000 0x0 0x1000 /* NVLW_MINION */
		       0x0 0x3b90000 0x0 0x4000 /* NVLW_NVL */
		       0x0 0x3b94000 0x0 0x1000 /* NVLW_SYNC2X */
		       0x0 0x3b96000 0x0 0x1000 /* NVLW_NVLTLC */
		       0x0 0x1f00000 0x0 0x20000>; /* MSSNVLINK_0 */
		clocks = <&bpmp_clks TEGRA234_CLK_NVHS_PLL0_MGMT>,
				<&bpmp_clks TEGRA234_CLK_PLLREFE_VCOOUT_GATED>,
				<&bpmp_clks TEGRA234_CLK_NVLINK_SYS>,
				<&bpmp_clks TEGRA234_CLK_PLLNVHS>,
				<&bpmp_clks TEGRA234_CLK_CLK_M>,
				<&bpmp_clks TEGRA234_CLK_NVLINK_PLL_TXCLK>,
				<&bpmp_clks TEGRA234_CLK_NVLINK_TX>;
		clock-names = "nvhs_pll0_mgmt", "pllrefe_vcoout_gated", "nvlink_sys", "pllnvhs", "clk_m", "nvlink_pll_txclk", "nvlink_tx";
		resets = <&bpmp_resets TEGRA194_RESET_MSSNVL>,
				<&bpmp_resets TEGRA194_RESET_NVHS_UPHY_PM>,
				<&bpmp_resets TEGRA194_RESET_NVHS_UPHY>,
				<&bpmp_resets TEGRA194_RESET_NVHS_UPHY_PLL0>,
				<&bpmp_resets TEGRA194_RESET_NVHS_UPHY_L0>,
				<&bpmp_resets TEGRA194_RESET_NVHS_UPHY_L1>,
				<&bpmp_resets TEGRA194_RESET_NVHS_UPHY_L2>,
				<&bpmp_resets TEGRA194_RESET_NVHS_UPHY_L3>,
				<&bpmp_resets TEGRA194_RESET_NVHS_UPHY_L4>,
				<&bpmp_resets TEGRA194_RESET_NVHS_UPHY_L5>,
				<&bpmp_resets TEGRA194_RESET_NVHS_UPHY_L6>,
				<&bpmp_resets TEGRA194_RESET_NVHS_UPHY_L7>;
		reset-names = "mssnvl", "nvhs_uphy_pm", "nvhs_uphy", "nvhs_uphy_pll0",
				"nvhs_uphy_l0", "nvhs_uphy_l1", "nvhs_uphy_l2",
				"nvhs_uphy_l3",	"nvhs_uphy_l4",	"nvhs_uphy_l5",
				"nvhs_uphy_l6",	"nvhs_uphy_l7";
		interrupts = <0 178 0x4>; /* NVLINK2HOST interrupt */
		status = "disabled";
	};

	nvpmodel {
		compatible = "nvidia,nvpmodel";
		clocks = <&bpmp_clks TEGRA234_CLK_EMC>,
				<&bpmp_clks TEGRA234_CLK_DLA0_CORE>,
				<&bpmp_clks TEGRA234_CLK_DLA1_CORE>,
				<&bpmp_clks TEGRA234_CLK_DLA0_FALCON>,
				<&bpmp_clks TEGRA234_CLK_DLA1_FALCON>,
				<&bpmp_clks TEGRA234_CLK_PVA0_VPS0>,
				<&bpmp_clks TEGRA234_CLK_PVA0_VPS1>,
				<&bpmp_clks TEGRA234_CLK_PVA1_VPS0>,
				<&bpmp_clks TEGRA234_CLK_PVA1_VPS1>,
				<&bpmp_clks TEGRA234_CLK_PVA0_AXI>,
				<&bpmp_clks TEGRA234_CLK_PVA1_AXI>;
		clock-names = "emc", "dla0_core", "dla1_core", "dla0_falcon", "dla1_falcon",
				"pva0_vps0", "pva0_vps1","pva1_vps0", "pva1_vps1",
				"pva0_axi", "pva1_axi";
		status = "okay";
	};

	nvdisplay@13800000 {
		compatible = "nvidia,tegra234-display";
		reg-names = "nvdisplay", "dpaux0", "dpaux1";
		reg = <0x0 0x13800000 0x0 0xEFFFF  /* nvdisplay */
		       0x0 0x155C0000 0x0 0xFFFF   /* dpaux0 */
		       0x0 0x155D0000 0x0 0xFFFF>; /* dpaux1 */
		interrupt-names = "nvdisplay", "dpaux0", "dpaux1";
		interrupts = <0 416 4
		              0 419 4
		              0 420 4>;
		clocks = <&bpmp_clks TEGRA234_CLK_NVDISPLAYHUB>,
				<&bpmp_clks TEGRA234_CLK_NVDISPLAY_DISP>,
				<&bpmp_clks TEGRA234_CLK_NVDISPLAY_P0>,
				<&bpmp_clks TEGRA234_CLK_NVDISPLAY_P1>;
		clock-names = "display_hub_clk",
				"display_disp_clk",
				"display_p_clk0",
				"display_p_clk1";
		status = "disabled";
		iommus = <&smmu TEGRA_SID_NVDISPLAY>;
		iso-smmu;
		non-coherent;
	};
};
